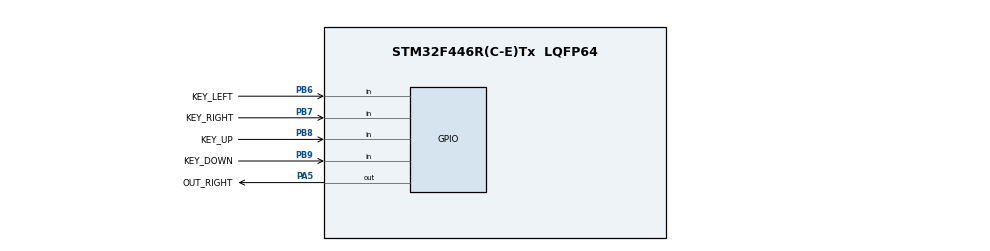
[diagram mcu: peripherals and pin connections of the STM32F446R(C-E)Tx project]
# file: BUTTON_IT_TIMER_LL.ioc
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Mcu.Family=STM32F4
Mcu.Name=STM32F446R(C-E)Tx
Mcu.Package=LQFP64
NVIC.PriorityGroup=NVIC_PRIORITYGROUP_4
NVIC.TIM1_UP_TIM10_IRQn=true\:2\:0\:true\:false\:true\:true\:true\:true
PA13.Mode=Serial_Wire
PA13.Signal=SYS_JTMS-SWDIO
PA14.Mode=Serial_Wire
PA14.Signal=SYS_JTCK-SWCLK
PA5.GPIO_Label=OUT_RIGHT
PA5.Signal=GPIO_Output
PB6.GPIO_Label=KEY_LEFT
PB6.GPIO_Mode=GPIO_MODE_INPUT
PB6.GPIO_PuPd=GPIO_PULLUP
PB6.Signal=GPIO_Input
PB7.GPIO_Label=KEY_RIGHT
PB7.GPIO_Mode=GPIO_MODE_INPUT
PB7.GPIO_PuPd=GPIO_PULLUP
PB7.Signal=GPIO_Input
PB8.GPIO_Label=KEY_UP
PB8.GPIO_Mode=GPIO_MODE_INPUT
PB8.GPIO_PuPd=GPIO_PULLUP
PB8.Signal=GPIO_Input
PB9.GPIO_Label=KEY_DOWN
PB9.GPIO_Mode=GPIO_MODE_INPUT
PB9.GPIO_PuPd=GPIO_PULLUP
PB9.Signal=GPIO_Input
PH0-OSC_IN.Mode=HSE-External-Oscillator
PH0-OSC_IN.Signal=RCC_OSC_IN
PH1-OSC_OUT.Mode=HSE-External-Oscillator
PH1-OSC_OUT.Signal=RCC_OSC_OUT
ProjectManager.HeapSize=0x200
ProjectManager.StackSize=0x400
ProjectManager.TargetToolchain=STM32CubeIDE
RCC.AHBFreq_Value=84000000
RCC.APB1CLKDivider=RCC_HCLK_DIV2
RCC.APB1Freq_Value=42000000
RCC.APB1TimFreq_Value=84000000
RCC.APB2Freq_Value=84000000
RCC.APB2TimFreq_Value=84000000
RCC.CortexFreq_Value=84000000
RCC.HCLKFreq_Value=84000000
RCC.HSE_VALUE=20000000
RCC.PLLM=8
RCC.PLLN=84
RCC.SYSCLKFreq_VALUE=84000000
RCC.SYSCLKSource=RCC_SYSCLKSOURCE_PLLCLK
RCC.USBFreq_Value=84000000
RCC.VCOOutputFreq_Value=168000000
TIM10.Period=420-1
TIM10.Prescaler=1000-1
VP_TIM10_VS_ClockSourceINT.Mode=Enable_Timer
board=custom

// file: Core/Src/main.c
/* USER CODE BEGIN Header */
/**
  ******************************************************************************
  * @file           : main.c
  * @brief          : Main program body
  ******************************************************************************
  * @attention
  *
  * Copyright (c) 2025 STMicroelectronics.
  * All rights reserved.
  *
  * This software is licensed under terms that can be found in the LICENSE file
  * in the root directory of this software component.
  * If no LICENSE file comes with this software, it is provided AS-IS.
  *
  ******************************************************************************
  */
/* USER CODE END Header */
#include "main.h"

/* USER CODE BEGIN Includes */
#include "keyboard.h"
/* USER CODE END Includes */

void SystemClock_Config(void);
static void MX_GPIO_Init(void);
static void MX_TIM10_Init(void);

int main(void)
{

  /* MCU Configuration--------------------------------------------------------*/

  /* Reset of all peripherals, Initializes the Flash interface and the Systick. */
  LL_APB2_GRP1_EnableClock(LL_APB2_GRP1_PERIPH_SYSCFG);
  LL_APB1_GRP1_EnableClock(LL_APB1_GRP1_PERIPH_PWR);

  /* System interrupt init*/
  NVIC_SetPriorityGrouping(NVIC_PRIORITYGROUP_4);

  /* SysTick_IRQn interrupt configuration */
  NVIC_SetPriority(SysTick_IRQn, NVIC_EncodePriority(NVIC_GetPriorityGrouping(),15, 0));

  /* Configure the system clock */
  SystemClock_Config();

  /* Initialize all configured peripherals */
  MX_GPIO_Init();
  MX_TIM10_Init();
  /* USER CODE BEGIN 2 */
  KEYB_Add_Button(KEY_LEFT_GPIO_Port , KEY_LEFT_Pin , KEYB_LEFT , KEYB_BUTTON_ACTIVE);
  KEYB_Add_Button(KEY_RIGHT_GPIO_Port, KEY_RIGHT_Pin, KEYB_RIGHT, KEYB_BUTTON_ACTIVE);
  KEYB_Add_Button(KEY_UP_GPIO_Port   , KEY_UP_Pin   , KEYB_UP   , KEYB_BUTTON_ACTIVE);
  KEYB_Add_Button(KEY_DOWN_GPIO_Port , KEY_DOWN_Pin , KEYB_DOWN , KEYB_BUTTON_ACTIVE);

  TIM10->DIER |= TIM_DIER_UIE;//Habilita la interrupción por desbordamiento (update interrupt)
  TIM10->CR1  |= TIM_CR1_CEN;//Inicia (habilita) el temporizador, esto hace que el timer empiece a contar.
  /* USER CODE END 2 */

  /* Infinite loop */
  /* USER CODE BEGIN WHILE */
  uint32_t keys = 0;

  while (1)
  {
	  keys = KEYB_Inkeys();
	  if (keys & (1<<KEYB_RIGHT)) LL_GPIO_TogglePin(OUT_RIGHT_GPIO_Port, OUT_RIGHT_Pin);
    /* USER CODE END WHILE */

  }
}

void SystemClock_Config(void)
{
  LL_FLASH_SetLatency(LL_FLASH_LATENCY_2);
  while(LL_FLASH_GetLatency()!= LL_FLASH_LATENCY_2)
  {
  }
  LL_PWR_SetRegulVoltageScaling(LL_PWR_REGU_VOLTAGE_SCALE3);
  LL_PWR_DisableOverDriveMode();
  LL_RCC_HSI_SetCalibTrimming(16);
  LL_RCC_HSI_Enable();

   /* Wait till HSI is ready */
  while(LL_RCC_HSI_IsReady() != 1)
  {

  }
  LL_RCC_PLL_ConfigDomain_SYS(LL_RCC_PLLSOURCE_HSI, LL_RCC_PLLM_DIV_8, 84, LL_RCC_PLLP_DIV_2);
  LL_RCC_PLL_Enable();

   /* Wait till PLL is ready */
  while(LL_RCC_PLL_IsReady() != 1)
  {

  }
  while (LL_PWR_IsActiveFlag_VOS() == 0)
  {
  }
  LL_RCC_SetAHBPrescaler(LL_RCC_SYSCLK_DIV_1);
  LL_RCC_SetAPB1Prescaler(LL_RCC_APB1_DIV_2);
  LL_RCC_SetAPB2Prescaler(LL_RCC_APB2_DIV_1);
  LL_RCC_SetSysClkSource(LL_RCC_SYS_CLKSOURCE_PLL);

   /* Wait till System clock is ready */
  while(LL_RCC_GetSysClkSource() != LL_RCC_SYS_CLKSOURCE_STATUS_PLL)
  {

  }
  LL_Init1msTick(84000000);
  LL_SetSystemCoreClock(84000000);
  LL_RCC_SetTIMPrescaler(LL_RCC_TIM_PRESCALER_TWICE);
}

static void MX_TIM10_Init(void)
{

  LL_TIM_InitTypeDef TIM_InitStruct = {0};

  /* Peripheral clock enable */
  LL_APB2_GRP1_EnableClock(LL_APB2_GRP1_PERIPH_TIM10);

  /* TIM10 interrupt Init */
  NVIC_SetPriority(TIM1_UP_TIM10_IRQn, NVIC_EncodePriority(NVIC_GetPriorityGrouping(),2, 0));
  NVIC_EnableIRQ(TIM1_UP_TIM10_IRQn);

  TIM_InitStruct.Prescaler = 999;
  TIM_InitStruct.CounterMode = LL_TIM_COUNTERMODE_UP;
  TIM_InitStruct.Autoreload = 420-LL_TIM_IC_FILTER_FDIV1_N2;
  TIM_InitStruct.ClockDivision = LL_TIM_CLOCKDIVISION_DIV1;
  LL_TIM_Init(TIM10, &TIM_InitStruct);
  LL_TIM_DisableARRPreload(TIM10);

}

static void MX_GPIO_Init(void)
{
  LL_GPIO_InitTypeDef GPIO_InitStruct = {0};

  /* GPIO Ports Clock Enable */
  LL_AHB1_GRP1_EnableClock(LL_AHB1_GRP1_PERIPH_GPIOH);
  LL_AHB1_GRP1_EnableClock(LL_AHB1_GRP1_PERIPH_GPIOA);
  LL_AHB1_GRP1_EnableClock(LL_AHB1_GRP1_PERIPH_GPIOB);

  /**/
  LL_GPIO_ResetOutputPin(OUT_RIGHT_GPIO_Port, OUT_RIGHT_Pin);

  /**/
  GPIO_InitStruct.Pin = OUT_RIGHT_Pin;
  GPIO_InitStruct.Mode = LL_GPIO_MODE_OUTPUT;
  GPIO_InitStruct.Speed = LL_GPIO_SPEED_FREQ_LOW;
  GPIO_InitStruct.OutputType = LL_GPIO_OUTPUT_PUSHPULL;
  GPIO_InitStruct.Pull = LL_GPIO_PULL_NO;
  LL_GPIO_Init(OUT_RIGHT_GPIO_Port, &GPIO_InitStruct);

  /**/
  GPIO_InitStruct.Pin = KEY_LEFT_Pin|KEY_RIGHT_Pin|KEY_UP_Pin|KEY_DOWN_Pin;
  GPIO_InitStruct.Mode = LL_GPIO_MODE_INPUT;
  GPIO_InitStruct.Pull = LL_GPIO_PULL_UP;
  LL_GPIO_Init(GPIOB, &GPIO_InitStruct);

}

void Error_Handler(void)
{
  __disable_irq();
  while (1)
  {
  }
}
